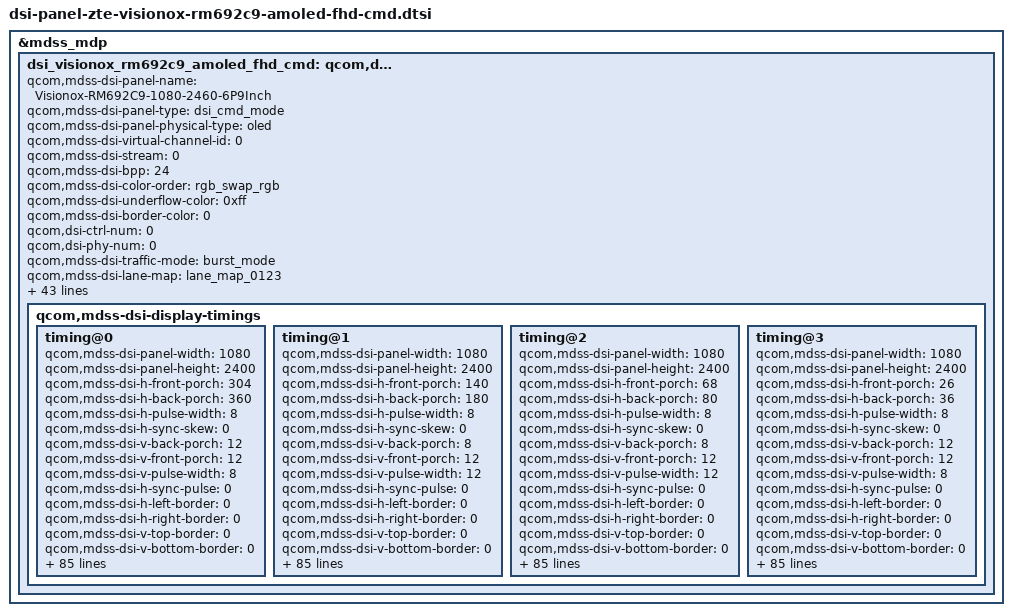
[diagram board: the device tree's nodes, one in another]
&mdss_mdp {
	dsi_visionox_rm692c9_amoled_fhd_cmd: qcom,dsi_visionox_rm692c9_cmd_display {
		qcom,mdss-dsi-panel-name = "Visionox-RM692C9-1080-2460-6P9Inch";
		qcom,mdss-dsi-panel-type = "dsi_cmd_mode";
		qcom,mdss-dsi-panel-physical-type = "oled";
		qcom,mdss-dsi-virtual-channel-id = <0>;
		qcom,mdss-dsi-stream = <0>;
		qcom,mdss-dsi-bpp = <24>;
		qcom,mdss-dsi-color-order = "rgb_swap_rgb";
		qcom,mdss-dsi-underflow-color = <0xff>;
		qcom,mdss-dsi-border-color = <0>;
		qcom,dsi-ctrl-num = <0>;
		qcom,dsi-phy-num = <0>;
		qcom,mdss-dsi-traffic-mode = "burst_mode";
		qcom,mdss-dsi-lane-map = "lane_map_0123";
		qcom,mdss-dsi-bllp-eof-power-mode;
		qcom,mdss-dsi-bllp-power-mode;
		qcom,mdss-dsi-lane-0-state;
		qcom,mdss-dsi-lane-1-state;
		qcom,mdss-dsi-lane-2-state;
		qcom,mdss-dsi-lane-3-state;
		qcom,mdss-dsi-lp11-init;
		qcom,mdss-dsi-tx-eot-append;
		qcom,mdss-dsi-dma-trigger = "trigger_sw";
		qcom,mdss-dsi-mdp-trigger = "none";
		qcom,mdss-dsi-reset-sequence = <1 10 0 10 1 50>;
		qcom,mdss-dsi-te-pin-select = <1>;
		qcom,mdss-dsi-te-dcs-command = <1>;
		qcom,mdss-dsi-te-check-enable;
		qcom,mdss-dsi-te-using-te-pin;
		qcom,mdss-dsi-bl-min-level = <1>;
		qcom,mdss-dsi-bl-max-level = <2047>;
		qcom,mdss-dsi-bl-pmic-control-type = "bl_ctrl_dcs";
		qcom,mdss-dsi-panel-hdr-enabled;
		qcom,mdss-dsi-panel-hdr-color-primaries = <14500 15500 34015 15980 13030 34670 6950 2565>;
		qcom,mdss-dsi-panel-peak-brightness = <6680000>;
		qcom,mdss-dsi-panel-blackness-level = <20>;
		qcom,mdss-pan-physical-width-dimension = <69>;
		qcom,mdss-pan-physical-height-dimension = <155>;
		qcom,bl-dsc-cmd-state = "dsi_lp_mode";
		zte,lcd_dimreg_value = <40>;
		zte,lcd_close_dimreg_value = <32>;
		zte,lcd_aod_bl_reg51_control;
		zte,lcd_hbm_bl_reg51_control;
		zte,lcd_hbm_max_bl = <4095>;
		qcom,panel-supply-entries = <&dsi_panel_pwr_supply>;
		qcom,mdss-brightness-max-level = <255>;
		qcom,platform-reset-gpio = <&tlmm 24 0>;
		zte,disp_iovdd_en_gpio = <&pm8350_gpios 9 1>;
		qcom,dsi-select-clocks = "mux_byte_clk0", "mux_pixel_clk0";
		qcom,dsi-panel-gpio-address = <0xf100000 0x1000>;
		qcom,dsi-panel-gpio-pins = <12 24 82>;
		qcom,dsi-panel-gpio-names = "reg-gpio", "reset-gpio", "platform-te-gpio";

		qcom,mdss-dsi-display-timings {
			timing@0 {
				qcom,mdss-dsi-panel-width = <1080>;
				qcom,mdss-dsi-panel-height = <2400>;
				qcom,mdss-dsi-h-front-porch = <304>;
				qcom,mdss-dsi-h-back-porch = <360>;
				qcom,mdss-dsi-h-pulse-width = <8>;
				qcom,mdss-dsi-h-sync-skew = <0>;
				qcom,mdss-dsi-v-back-porch = <12>;
				qcom,mdss-dsi-v-front-porch = <12>;
				qcom,mdss-dsi-v-pulse-width = <8>;
				qcom,mdss-dsi-h-sync-pulse = <0>;
				qcom,mdss-dsi-h-left-border = <0>;
				qcom,mdss-dsi-h-right-border = <0>;
				qcom,mdss-dsi-v-top-border = <0>;
				qcom,mdss-dsi-v-bottom-border = <0>;
				qcom,mdss-dsi-panel-framerate = <60>;
				qcom,mdss-dsi-panel-clockrate = <903540000>;
				qcom,mdss-dsi-on-command = [15 01 00 00 00 00 02 fe 00
					15 01 00 00 00 00 02 55 00
					15 01 00 00 00 00 02 fe 34
					15 01 00 00 00 00 02 47 03
					15 01 00 00 00 00 02 48 00
					15 01 00 00 00 00 02 00 00
					15 01 00 00 00 00 02 fe 34
					15 01 00 00 00 00 02 9f 38
					15 01 00 00 00 00 02 a0 04
					15 01 00 00 00 00 02 1e 00
					15 01 00 00 00 00 02 1f 00
					15 01 00 00 00 00 02 20 00
					15 01 00 00 00 00 02 22 00
					15 01 00 00 00 00 02 21 70
					15 01 00 00 00 00 02 23 f8
					15 01 00 00 00 00 02 24 77
					15 01 00 00 00 00 02 25 f8
					15 01 00 00 00 00 02 26 f8
					15 01 00 00 00 00 02 2f 00
					15 01 00 00 00 00 02 30 00
					15 01 00 00 00 00 02 31 00
					15 01 00 00 00 00 02 32 00
					15 01 00 00 00 00 02 33 00
					15 01 00 00 00 00 02 34 00
					15 01 00 00 00 00 02 35 00
					15 01 00 00 00 00 02 36 4c
					15 01 00 00 00 00 02 37 00
					15 01 00 00 00 00 02 38 e9
					15 01 00 00 00 00 02 39 01
					15 01 00 00 00 00 02 3a 53
					15 01 00 00 00 00 02 3b 00
					15 01 00 00 00 00 02 3d 00
					15 01 00 00 00 00 02 3f 00
					15 01 00 00 00 00 02 40 00
					15 01 00 00 00 00 02 41 00
					15 01 00 00 00 00 02 42 00
					15 01 00 00 00 00 02 fe 12
					15 01 00 00 05 00 02 83 10
					15 01 00 00 00 00 02 fe 40
					15 01 00 00 00 00 02 bd 00
					15 01 00 00 00 00 02 fe a1
					15 01 00 00 00 00 02 cd 6b
					15 01 00 00 00 00 02 ce bb
					15 01 00 00 00 00 02 fe d1
					15 01 00 00 00 00 02 b4 01
					15 01 00 00 00 00 02 fe 38
					15 01 00 00 00 00 02 17 0f
					15 01 00 00 00 00 02 18 0f
					15 01 00 00 00 00 02 fe 42
					15 01 00 00 00 00 02 21 44
					15 01 00 00 00 00 02 fe 00
					15 01 00 00 00 00 02 fa 01
					15 01 00 00 00 00 02 c2 08
					15 01 00 00 00 00 02 35 00
					39 01 00 00 00 00 03 51 00 00
					05 01 00 00 50 00 01 11
					05 01 00 00 0a 00 01 29
				];
				qcom,mdss-dsi-off-command = [05 01 00 00 64 00 01 28
					05 01 00 00 0a 00 01 10
				];
				qcom,mdss-dsi-on-command-state = "dsi_lp_mode";
				qcom,mdss-dsi-off-command-state = "dsi_lp_mode";
				qcom,mdss-dsi-lp1-command = [15 01 00 00 00 00 02 fe a0
					15 01 00 00 00 00 02 25 c0
					15 01 00 00 00 00 02 fe 00
					05 01 00 00 00 00 01 39
				];
				qcom,mdss-dsi-lp1-command-state = "dsi_lp_mode";
				qcom,mdss-dsi-nolp-command = [15 01 00 00 00 00 02 fe 00
					05 01 00 00 00 00 01 38
					15 01 00 00 00 00 02 fe a0
					15 01 00 00 00 00 02 25 40
					15 01 00 00 00 00 02 fe 00
				];
				qcom,mdss-dsi-nolp-command-state = "dsi_lp_mode";
				qcom,mdss-dsi-timing-switch-command = [15 01 00 00 00 00 02 fe 40
					15 01 00 00 00 00 02 bd 00
					15 01 00 00 00 00 02 fe 00
				];
				qcom,mdss-dsi-timing-switch-command-state = "dsi_lp_mode";
				zte,mdss-dsi-aod-low-commands = [39 01 00 00 00 00 03 51 00 ff];
				zte,mdss-dsi-aod-mid-commands = [39 01 00 00 00 00 03 51 07 ff];
				zte,mdss-dsi-aod-high-commands = [39 01 00 00 00 00 03 51 0f ff];
				zte,mdss-dsi-hbm-on-commands = [15 01 00 00 00 00 02 53 20
					39 01 00 00 00 00 03 51 0f ff
				];
				zte,mdss-dsi-hbm-off-commands = [39 01 00 00 00 00 03 51 03 ff];
				zte,mdss-dsi-global-hbm-on-commands = [15 01 00 00 00 00 02 83 01];
				zte,mdss-dsi-global-hbm-off-commands = [15 01 00 00 00 00 02 83 00];
				zte,mdss-dsi-acl-off-commands = [15 01 00 00 00 00 02 fe 00
					15 01 00 00 00 00 02 55 00
				];
				zte,mdss-dsi-acl-low-commands = [15 01 00 00 00 00 02 fe 00
					15 01 00 00 00 00 02 55 01
				];
				zte,mdss-dsi-acl-mid-commands = [15 01 00 00 00 00 02 fe 00
					15 01 00 00 00 00 02 55 02
				];
				zte,mdss-dsi-acl-high-commands = [15 01 00 00 00 00 02 fe 00
					15 01 00 00 00 00 02 55 03
				];
				zte,mdss-dsi-elvdd-46-commands = [15 01 00 00 00 00 02 fe 40
					15 01 00 00 00 00 02 b2 54
					15 01 00 00 00 00 02 fe 00
				];
				zte,mdss-dsi-color-original-commands = [15 01 00 00 00 00 02 fe 12
					15 01 00 00 00 00 02 83 00
					15 01 00 00 05 00 02 fe 00
				];
				zte,mdss-dsi-color-srgb-commands = [15 01 00 00 00 00 02 fe 12
					15 01 00 00 00 00 02 83 20
					15 01 00 00 05 00 02 fe 00
				];
				zte,mdss-dsi-color-p3-commands = [15 01 00 00 00 00 02 fe 12
					15 01 00 00 00 00 02 83 10
					15 01 00 00 05 00 02 fe 00
				];
				zte,mdss-dsi-color-original-commands-state = "dsi_lp_mode";
				zte,mdss-dsi-color-srgb-commands-state = "dsi_lp_mode";
				zte,mdss-dsi-color-p3-commands-state = "dsi_lp_mode";
				zte,mdss-dsi-hbm-on-commands-state = "dsi_lp_mode";
				zte,mdss-dsi-hbm-off-commands-state = "dsi_lp_mode";
				zte,mdss-dsi-aod-low-commands-state = "dsi_lp_mode";
				zte,mdss-dsi-aod-mid-commands-state = "dsi_lp_mode";
				zte,mdss-dsi-aod-high-commands-state = "dsi_lp_mode";
				zte,mdss-dsi-acl-off-commands-state = "dsi_lp_mode";
				zte,mdss-dsi-acl-low-commands-state = "dsi_lp_mode";
				zte,mdss-dsi-acl-mid-commands-state = "dsi_lp_mode";
				zte,mdss-dsi-acl-high-commands-state = "dsi_lp_mode";
				zte,mdss-dsi-elvdd-46-commands-state = "dsi_lp_mode";
				qcom,compression-mode = "dsc";
				qcom,mdss-dsc-slice-height = <20>;
				qcom,mdss-dsc-slice-width = <540>;
				qcom,mdss-dsc-slice-per-pkt = <2>;
				qcom,mdss-dsc-bit-per-component = <8>;
				qcom,mdss-dsc-bit-per-pixel = <8>;
				qcom,mdss-dsc-block-prediction-enable;
				qcom,mdss-dsi-panel-phy-timings = [00 1e 08 07 18 16 08 08 08 02 04 00 1a 0d];
				qcom,display-topology = <2 2 1>;
				qcom,default-topology-index = <0>;
			};

			timing@1 {
				qcom,mdss-dsi-panel-width = <1080>;
				qcom,mdss-dsi-panel-height = <2400>;
				qcom,mdss-dsi-h-front-porch = <140>;
				qcom,mdss-dsi-h-back-porch = <180>;
				qcom,mdss-dsi-h-pulse-width = <8>;
				qcom,mdss-dsi-h-sync-skew = <0>;
				qcom,mdss-dsi-v-back-porch = <8>;
				qcom,mdss-dsi-v-front-porch = <12>;
				qcom,mdss-dsi-v-pulse-width = <12>;
				qcom,mdss-dsi-h-sync-pulse = <0>;
				qcom,mdss-dsi-h-left-border = <0>;
				qcom,mdss-dsi-h-right-border = <0>;
				qcom,mdss-dsi-v-top-border = <0>;
				qcom,mdss-dsi-v-bottom-border = <0>;
				qcom,mdss-dsi-panel-framerate = <90>;
				qcom,mdss-dsi-panel-clockrate = <903640000>;
				qcom,mdss-dsi-on-command = [15 01 00 00 00 00 02 fe 00
					15 01 00 00 00 00 02 55 00
					15 01 00 00 00 00 02 fe 34
					15 01 00 00 00 00 02 47 03
					15 01 00 00 00 00 02 48 00
					15 01 00 00 00 00 02 00 00
					15 01 00 00 00 00 02 fe 34
					15 01 00 00 00 00 02 9f 38
					15 01 00 00 00 00 02 a0 04
					15 01 00 00 00 00 02 1e 00
					15 01 00 00 00 00 02 1f 00
					15 01 00 00 00 00 02 20 00
					15 01 00 00 00 00 02 22 00
					15 01 00 00 00 00 02 21 70
					15 01 00 00 00 00 02 23 f8
					15 01 00 00 00 00 02 24 77
					15 01 00 00 00 00 02 25 f8
					15 01 00 00 00 00 02 26 f8
					15 01 00 00 00 00 02 2f 00
					15 01 00 00 00 00 02 30 00
					15 01 00 00 00 00 02 31 00
					15 01 00 00 00 00 02 32 00
					15 01 00 00 00 00 02 33 00
					15 01 00 00 00 00 02 34 00
					15 01 00 00 00 00 02 35 00
					15 01 00 00 00 00 02 36 4c
					15 01 00 00 00 00 02 37 00
					15 01 00 00 00 00 02 38 e9
					15 01 00 00 00 00 02 39 01
					15 01 00 00 00 00 02 3a 53
					15 01 00 00 00 00 02 3b 00
					15 01 00 00 00 00 02 3d 00
					15 01 00 00 00 00 02 3f 00
					15 01 00 00 00 00 02 40 00
					15 01 00 00 00 00 02 41 00
					15 01 00 00 00 00 02 42 00
					15 01 00 00 00 00 02 fe 12
					15 01 00 00 05 00 02 83 10
					15 01 00 00 00 00 02 fe 40
					15 01 00 00 00 00 02 bd 05
					15 01 00 00 00 00 02 fe a1
					15 01 00 00 00 00 02 cd 6b
					15 01 00 00 00 00 02 ce bb
					15 01 00 00 00 00 02 fe d1
					15 01 00 00 00 00 02 b4 01
					15 01 00 00 00 00 02 fe 38
					15 01 00 00 00 00 02 17 0f
					15 01 00 00 00 00 02 18 0f
					15 01 00 00 00 00 02 fe 42
					15 01 00 00 00 00 02 21 44
					15 01 00 00 00 00 02 fe 00
					15 01 00 00 00 00 02 fa 01
					15 01 00 00 00 00 02 c2 08
					15 01 00 00 00 00 02 35 00
					39 01 00 00 00 00 03 51 00 00
					05 01 00 00 50 00 01 11
					05 01 00 00 0a 00 01 29
				];
				qcom,mdss-dsi-off-command = [05 01 00 00 64 00 01 28
					05 01 00 00 0a 00 01 10
				];
				qcom,mdss-dsi-on-command-state = "dsi_lp_mode";
				qcom,mdss-dsi-off-command-state = "dsi_lp_mode";
				qcom,mdss-dsi-lp1-command = [15 01 00 00 00 00 02 fe a0
					15 01 00 00 00 00 02 25 c0
					15 01 00 00 00 00 02 fe 00
					05 01 00 00 00 00 01 39
				];
				qcom,mdss-dsi-lp1-command-state = "dsi_lp_mode";
				qcom,mdss-dsi-nolp-command = [15 01 00 00 00 00 02 fe 00
					05 01 00 00 00 00 01 38
					15 01 00 00 00 00 02 fe a0
					15 01 00 00 00 00 02 25 40
					15 01 00 00 00 00 02 fe 00
				];
				qcom,mdss-dsi-nolp-command-state = "dsi_lp_mode";
				qcom,mdss-dsi-timing-switch-command = [15 01 00 00 00 00 02 fe 40
					15 01 00 00 00 00 02 bd 05
					15 01 00 00 00 00 02 fe 00
				];
				qcom,mdss-dsi-timing-switch-command-state = "dsi_lp_mode";
				zte,mdss-dsi-aod-low-commands = [39 01 00 00 00 00 03 51 00 ff];
				zte,mdss-dsi-aod-mid-commands = [39 01 00 00 00 00 03 51 07 ff];
				zte,mdss-dsi-aod-high-commands = [39 01 00 00 00 00 03 51 0f ff];
				zte,mdss-dsi-hbm-on-commands = [15 01 00 00 00 00 02 53 20
					39 01 00 00 00 00 03 51 0f ff
				];
				zte,mdss-dsi-hbm-off-commands = [39 01 00 00 00 00 03 51 03 ff];
				zte,mdss-dsi-global-hbm-on-commands = [15 01 00 00 00 00 02 83 01];
				zte,mdss-dsi-global-hbm-off-commands = [15 01 00 00 00 00 02 83 00];
				zte,mdss-dsi-acl-off-commands = [15 01 00 00 00 00 02 fe 00
					15 01 00 00 00 00 02 55 00
				];
				zte,mdss-dsi-acl-low-commands = [15 01 00 00 00 00 02 fe 00
					15 01 00 00 00 00 02 55 01
				];
				zte,mdss-dsi-acl-mid-commands = [15 01 00 00 00 00 02 fe 00
					15 01 00 00 00 00 02 55 02
				];
				zte,mdss-dsi-acl-high-commands = [15 01 00 00 00 00 02 fe 00
					15 01 00 00 00 00 02 55 03
				];
				zte,mdss-dsi-elvdd-46-commands = [15 01 00 00 00 00 02 fe 40
					15 01 00 00 00 00 02 b2 54
					15 01 00 00 00 00 02 fe 00
				];
				zte,mdss-dsi-color-original-commands = [15 01 00 00 00 00 02 fe 12
					15 01 00 00 00 00 02 83 00
					15 01 00 00 05 00 02 fe 00
				];
				zte,mdss-dsi-color-srgb-commands = [15 01 00 00 00 00 02 fe 12
					15 01 00 00 00 00 02 83 20
					15 01 00 00 05 00 02 fe 00
				];
				zte,mdss-dsi-color-p3-commands = [15 01 00 00 00 00 02 fe 12
					15 01 00 00 00 00 02 83 10
					15 01 00 00 05 00 02 fe 00
				];
				zte,mdss-dsi-color-original-commands-state = "dsi_lp_mode";
				zte,mdss-dsi-color-srgb-commands-state = "dsi_lp_mode";
				zte,mdss-dsi-color-p3-commands-state = "dsi_lp_mode";
				zte,mdss-dsi-hbm-on-commands-state = "dsi_lp_mode";
				zte,mdss-dsi-hbm-off-commands-state = "dsi_lp_mode";
				zte,mdss-dsi-aod-low-commands-state = "dsi_lp_mode";
				zte,mdss-dsi-aod-mid-commands-state = "dsi_lp_mode";
				zte,mdss-dsi-aod-high-commands-state = "dsi_lp_mode";
				zte,mdss-dsi-acl-off-commands-state = "dsi_lp_mode";
				zte,mdss-dsi-acl-low-commands-state = "dsi_lp_mode";
				zte,mdss-dsi-acl-mid-commands-state = "dsi_lp_mode";
				zte,mdss-dsi-acl-high-commands-state = "dsi_lp_mode";
				zte,mdss-dsi-elvdd-46-commands-state = "dsi_lp_mode";
				qcom,compression-mode = "dsc";
				qcom,mdss-dsc-slice-height = <20>;
				qcom,mdss-dsc-slice-width = <540>;
				qcom,mdss-dsc-slice-per-pkt = <2>;
				qcom,mdss-dsc-bit-per-component = <8>;
				qcom,mdss-dsc-bit-per-pixel = <8>;
				qcom,mdss-dsc-block-prediction-enable;
				qcom,mdss-dsi-panel-phy-timings = [00 1e 08 07 18 16 08 08 08 02 04 00 1a 0d];
				qcom,display-topology = <2 2 1>;
				qcom,default-topology-index = <0>;
			};

			timing@2 {
				qcom,mdss-dsi-panel-width = <1080>;
				qcom,mdss-dsi-panel-height = <2400>;
				qcom,mdss-dsi-h-front-porch = <68>;
				qcom,mdss-dsi-h-back-porch = <80>;
				qcom,mdss-dsi-h-pulse-width = <8>;
				qcom,mdss-dsi-h-sync-skew = <0>;
				qcom,mdss-dsi-v-back-porch = <8>;
				qcom,mdss-dsi-v-front-porch = <12>;
				qcom,mdss-dsi-v-pulse-width = <12>;
				qcom,mdss-dsi-h-sync-pulse = <0>;
				qcom,mdss-dsi-h-left-border = <0>;
				qcom,mdss-dsi-h-right-border = <0>;
				qcom,mdss-dsi-v-top-border = <0>;
				qcom,mdss-dsi-v-bottom-border = <0>;
				qcom,mdss-dsi-panel-framerate = <120>;
				qcom,mdss-dsi-panel-clockrate = <903740000>;
				qcom,mdss-dsi-on-command = [15 01 00 00 00 00 02 fe 00
					15 01 00 00 00 00 02 55 00
					15 01 00 00 00 00 02 fe 34
					15 01 00 00 00 00 02 47 03
					15 01 00 00 00 00 02 48 00
					15 01 00 00 00 00 02 00 00
					15 01 00 00 00 00 02 fe 34
					15 01 00 00 00 00 02 47 03
					15 01 00 00 00 00 02 48 00
					15 01 00 00 00 00 02 00 00
					15 01 00 00 00 00 02 fe 34
					15 01 00 00 00 00 02 9f 38
					15 01 00 00 00 00 02 a0 04
					15 01 00 00 00 00 02 1e 00
					15 01 00 00 00 00 02 1f 00
					15 01 00 00 00 00 02 20 00
					15 01 00 00 00 00 02 22 00
					15 01 00 00 00 00 02 21 70
					15 01 00 00 00 00 02 23 f8
					15 01 00 00 00 00 02 24 77
					15 01 00 00 00 00 02 25 f8
					15 01 00 00 00 00 02 26 f8
					15 01 00 00 00 00 02 2f 00
					15 01 00 00 00 00 02 30 00
					15 01 00 00 00 00 02 31 00
					15 01 00 00 00 00 02 32 00
					15 01 00 00 00 00 02 33 00
					15 01 00 00 00 00 02 34 00
					15 01 00 00 00 00 02 35 00
					15 01 00 00 00 00 02 36 4c
					15 01 00 00 00 00 02 37 00
					15 01 00 00 00 00 02 38 e9
					15 01 00 00 00 00 02 39 01
					15 01 00 00 00 00 02 3a 53
					15 01 00 00 00 00 02 3b 00
					15 01 00 00 00 00 02 3d 00
					15 01 00 00 00 00 02 3f 00
					15 01 00 00 00 00 02 40 00
					15 01 00 00 00 00 02 41 00
					15 01 00 00 00 00 02 42 00
					15 01 00 00 00 00 02 fe 12
					15 01 00 00 05 00 02 83 10
					15 01 00 00 00 00 02 fe 40
					15 01 00 00 00 00 02 bd 06
					15 01 00 00 00 00 02 fe a1
					15 01 00 00 00 00 02 cd 6b
					15 01 00 00 00 00 02 ce bb
					15 01 00 00 00 00 02 fe d1
					15 01 00 00 00 00 02 b4 01
					15 01 00 00 00 00 02 fe 38
					15 01 00 00 00 00 02 17 0f
					15 01 00 00 00 00 02 18 0f
					15 01 00 00 00 00 02 fe 42
					15 01 00 00 00 00 02 21 44
					15 01 00 00 00 00 02 fe 00
					15 01 00 00 00 00 02 fa 01
					15 01 00 00 00 00 02 c2 08
					15 01 00 00 00 00 02 35 00
					39 01 00 00 00 00 03 51 00 00
					05 01 00 00 50 00 01 11
					05 01 00 00 0a 00 01 29
				];
				qcom,mdss-dsi-off-command = [05 01 00 00 64 00 01 28
					05 01 00 00 0a 00 01 10
				];
				qcom,mdss-dsi-lp1-command = [15 01 00 00 00 00 02 fe a0
					15 01 00 00 00 00 02 25 c0
					15 01 00 00 00 00 02 fe 00
					05 01 00 00 00 00 01 39
				];
				qcom,mdss-dsi-lp1-command-state = "dsi_lp_mode";
				qcom,mdss-dsi-nolp-command = [15 01 00 00 00 00 02 fe 00
					05 01 00 00 00 00 01 38
					15 01 00 00 00 00 02 fe a0
					15 01 00 00 00 00 02 25 40
					15 01 00 00 00 00 02 fe 00
				];
				qcom,mdss-dsi-nolp-command-state = "dsi_lp_mode";
				qcom,mdss-dsi-on-command-state = "dsi_lp_mode";
				qcom,mdss-dsi-off-command-state = "dsi_lp_mode";
				qcom,mdss-dsi-timing-switch-command = [15 01 00 00 00 00 02 fe 40
					15 01 00 00 00 00 02 bd 06
					15 01 00 00 00 00 02 fe 00
				];
				qcom,mdss-dsi-timing-switch-command-state = "dsi_lp_mode";
				zte,mdss-dsi-aod-low-commands = [39 01 00 00 00 00 03 51 00 ff];
				zte,mdss-dsi-aod-mid-commands = [39 01 00 00 00 00 03 51 07 ff];
				zte,mdss-dsi-aod-high-commands = [39 01 00 00 00 00 03 51 0f ff];
				zte,mdss-dsi-hbm-on-commands = [15 01 00 00 00 00 02 53 20
					39 01 00 00 00 00 03 51 0f ff
				];
				zte,mdss-dsi-hbm-off-commands = [39 01 00 00 00 00 03 51 03 ff];
				zte,mdss-dsi-global-hbm-on-commands = [15 01 00 00 00 00 02 83 01];
				zte,mdss-dsi-global-hbm-off-commands = [15 01 00 00 00 00 02 83 00];
				zte,mdss-dsi-acl-off-commands = [15 01 00 00 00 00 02 fe 00
					15 01 00 00 00 00 02 55 00
				];
				zte,mdss-dsi-acl-low-commands = [15 01 00 00 00 00 02 fe 00
					15 01 00 00 00 00 02 55 01
				];
				zte,mdss-dsi-acl-mid-commands = [15 01 00 00 00 00 02 fe 00
					15 01 00 00 00 00 02 55 02
				];
				zte,mdss-dsi-acl-high-commands = [15 01 00 00 00 00 02 fe 00
					15 01 00 00 00 00 02 55 03
				];
				zte,mdss-dsi-elvdd-46-commands = [15 01 00 00 00 00 02 fe 40
					15 01 00 00 00 00 02 b2 54
					15 01 00 00 00 00 02 fe 00
				];
				zte,mdss-dsi-color-original-commands = [15 01 00 00 00 00 02 fe 12
					15 01 00 00 00 00 02 83 00
					15 01 00 00 05 00 02 fe 00
				];
				zte,mdss-dsi-color-srgb-commands = [15 01 00 00 00 00 02 fe 12
					15 01 00 00 00 00 02 83 20
					15 01 00 00 05 00 02 fe 00
				];
				zte,mdss-dsi-color-p3-commands = [15 01 00 00 00 00 02 fe 12
					15 01 00 00 00 00 02 83 10
					15 01 00 00 05 00 02 fe 00
				];
				zte,mdss-dsi-color-original-commands-state = "dsi_lp_mode";
				zte,mdss-dsi-color-srgb-commands-state = "dsi_lp_mode";
				zte,mdss-dsi-color-p3-commands-state = "dsi_lp_mode";
				zte,mdss-dsi-hbm-on-commands-state = "dsi_lp_mode";
				zte,mdss-dsi-hbm-off-commands-state = "dsi_lp_mode";
				zte,mdss-dsi-aod-low-commands-state = "dsi_lp_mode";
				zte,mdss-dsi-aod-mid-commands-state = "dsi_lp_mode";
				zte,mdss-dsi-aod-high-commands-state = "dsi_lp_mode";
				zte,mdss-dsi-acl-off-commands-state = "dsi_lp_mode";
				zte,mdss-dsi-acl-low-commands-state = "dsi_lp_mode";
				zte,mdss-dsi-acl-mid-commands-state = "dsi_lp_mode";
				zte,mdss-dsi-acl-high-commands-state = "dsi_lp_mode";
				zte,mdss-dsi-elvdd-46-commands-state = "dsi_lp_mode";
				qcom,compression-mode = "dsc";
				qcom,mdss-dsc-slice-height = <20>;
				qcom,mdss-dsc-slice-width = <540>;
				qcom,mdss-dsc-slice-per-pkt = <2>;
				qcom,mdss-dsc-bit-per-component = <8>;
				qcom,mdss-dsc-bit-per-pixel = <8>;
				qcom,mdss-dsc-block-prediction-enable;
				qcom,mdss-dsi-panel-phy-timings = [00 1e 08 07 18 16 08 08 08 02 04 00 1a 0d];
				qcom,display-topology = <2 2 1>;
				qcom,default-topology-index = <0>;
			};

			timing@3 {
				qcom,mdss-dsi-panel-width = <1080>;
				qcom,mdss-dsi-panel-height = <2400>;
				qcom,mdss-dsi-h-front-porch = <26>;
				qcom,mdss-dsi-h-back-porch = <36>;
				qcom,mdss-dsi-h-pulse-width = <8>;
				qcom,mdss-dsi-h-sync-skew = <0>;
				qcom,mdss-dsi-v-back-porch = <12>;
				qcom,mdss-dsi-v-front-porch = <12>;
				qcom,mdss-dsi-v-pulse-width = <8>;
				qcom,mdss-dsi-h-sync-pulse = <0>;
				qcom,mdss-dsi-h-left-border = <0>;
				qcom,mdss-dsi-h-right-border = <0>;
				qcom,mdss-dsi-v-top-border = <0>;
				qcom,mdss-dsi-v-bottom-border = <0>;
				qcom,mdss-dsi-panel-framerate = <144>;
				qcom,mdss-dsi-panel-clockrate = <903840000>;
				qcom,mdss-dsi-on-command = [15 01 00 00 00 00 02 fe 00
					15 01 00 00 00 00 02 55 00
					15 01 00 00 00 00 02 fe 34
					15 01 00 00 00 00 02 47 03
					15 01 00 00 00 00 02 48 00
					15 01 00 00 00 00 02 00 00
					15 01 00 00 00 00 02 fe 34
					15 01 00 00 00 00 02 9f 38
					15 01 00 00 00 00 02 a0 04
					15 01 00 00 00 00 02 1e 00
					15 01 00 00 00 00 02 1f 00
					15 01 00 00 00 00 02 20 00
					15 01 00 00 00 00 02 22 00
					15 01 00 00 00 00 02 21 70
					15 01 00 00 00 00 02 23 f8
					15 01 00 00 00 00 02 24 77
					15 01 00 00 00 00 02 25 f8
					15 01 00 00 00 00 02 26 f8
					15 01 00 00 00 00 02 2f 00
					15 01 00 00 00 00 02 30 00
					15 01 00 00 00 00 02 31 00
					15 01 00 00 00 00 02 32 00
					15 01 00 00 00 00 02 33 00
					15 01 00 00 00 00 02 34 00
					15 01 00 00 00 00 02 35 00
					15 01 00 00 00 00 02 36 4c
					15 01 00 00 00 00 02 37 00
					15 01 00 00 00 00 02 38 e9
					15 01 00 00 00 00 02 39 01
					15 01 00 00 00 00 02 3a 53
					15 01 00 00 00 00 02 3b 00
					15 01 00 00 00 00 02 3d 00
					15 01 00 00 00 00 02 3f 00
					15 01 00 00 00 00 02 40 00
					15 01 00 00 00 00 02 41 00
					15 01 00 00 00 00 02 42 00
					15 01 00 00 00 00 02 fe 12
					15 01 00 00 05 00 02 83 10
					15 01 00 00 00 00 02 fe 40
					15 01 00 00 00 00 02 bd 07
					15 01 00 00 00 00 02 fe a1
					15 01 00 00 00 00 02 cd 6b
					15 01 00 00 00 00 02 ce bb
					15 01 00 00 00 00 02 fe d1
					15 01 00 00 00 00 02 b4 01
					15 01 00 00 00 00 02 fe 38
					15 01 00 00 00 00 02 17 0f
					15 01 00 00 00 00 02 18 0f
					15 01 00 00 00 00 02 fe 42
					15 01 00 00 00 00 02 21 44
					15 01 00 00 00 00 02 fe 00
					15 01 00 00 00 00 02 fa 01
					15 01 00 00 00 00 02 c2 08
					15 01 00 00 00 00 02 35 00
					39 01 00 00 00 00 03 51 00 00
					05 01 00 00 50 00 01 11
					05 01 00 00 0a 00 01 29
				];
				qcom,mdss-dsi-off-command = [05 01 00 00 64 00 01 28
					05 01 00 00 0a 00 01 10
				];
				qcom,mdss-dsi-on-command-state = "dsi_lp_mode";
				qcom,mdss-dsi-off-command-state = "dsi_lp_mode";
				qcom,mdss-dsi-lp1-command = [15 01 00 00 00 00 02 fe a0
					15 01 00 00 00 00 02 25 c0
					15 01 00 00 00 00 02 fe 00
					05 01 00 00 00 00 01 39
				];
				qcom,mdss-dsi-lp1-command-state = "dsi_lp_mode";
				qcom,mdss-dsi-nolp-command = [15 01 00 00 00 00 02 fe 00
					05 01 00 00 00 00 01 38
					15 01 00 00 00 00 02 fe a0
					15 01 00 00 00 00 02 25 40
					15 01 00 00 00 00 02 fe 00
				];
				qcom,mdss-dsi-nolp-command-state = "dsi_lp_mode";
				qcom,mdss-dsi-timing-switch-command = [15 01 00 00 00 00 02 fe 40
					15 01 00 00 00 00 02 bd 07
					15 01 00 00 00 00 02 fe 00
				];
				qcom,mdss-dsi-timing-switch-command-state = "dsi_lp_mode";
				zte,mdss-dsi-aod-low-commands = [39 01 00 00 00 00 03 51 00 ff];
				zte,mdss-dsi-aod-mid-commands = [39 01 00 00 00 00 03 51 07 ff];
				zte,mdss-dsi-aod-high-commands = [39 01 00 00 00 00 03 51 0f ff];
				zte,mdss-dsi-hbm-on-commands = [15 01 00 00 00 00 02 53 20
					39 01 00 00 00 00 03 51 0f ff
				];
				zte,mdss-dsi-hbm-off-commands = [39 01 00 00 00 00 03 51 03 ff];
				zte,mdss-dsi-global-hbm-on-commands = [15 01 00 00 00 00 02 83 01];
				zte,mdss-dsi-global-hbm-off-commands = [15 01 00 00 00 00 02 83 00];
				zte,mdss-dsi-acl-off-commands = [15 01 00 00 00 00 02 fe 00
					15 01 00 00 00 00 02 55 00
				];
				zte,mdss-dsi-acl-low-commands = [15 01 00 00 00 00 02 fe 00
					15 01 00 00 00 00 02 55 01
				];
				zte,mdss-dsi-acl-mid-commands = [15 01 00 00 00 00 02 fe 00
					15 01 00 00 00 00 02 55 02
				];
				zte,mdss-dsi-acl-high-commands = [15 01 00 00 00 00 02 fe 00
					15 01 00 00 00 00 02 55 03
				];
				zte,mdss-dsi-elvdd-46-commands = [15 01 00 00 00 00 02 fe 40
					15 01 00 00 00 00 02 b2 54
					15 01 00 00 00 00 02 fe 00
				];
				zte,mdss-dsi-color-original-commands = [15 01 00 00 00 00 02 fe 12
					15 01 00 00 00 00 02 83 00
					15 01 00 00 05 00 02 fe 00
				];
				zte,mdss-dsi-color-srgb-commands = [15 01 00 00 00 00 02 fe 12
					15 01 00 00 00 00 02 83 20
					15 01 00 00 05 00 02 fe 00
				];
				zte,mdss-dsi-color-p3-commands = [15 01 00 00 00 00 02 fe 12
					15 01 00 00 00 00 02 83 10
					15 01 00 00 05 00 02 fe 00
				];
				zte,mdss-dsi-color-original-commands-state = "dsi_lp_mode";
				zte,mdss-dsi-color-srgb-commands-state = "dsi_lp_mode";
				zte,mdss-dsi-color-p3-commands-state = "dsi_lp_mode";
				zte,mdss-dsi-hbm-on-commands-state = "dsi_lp_mode";
				zte,mdss-dsi-hbm-off-commands-state = "dsi_lp_mode";
				zte,mdss-dsi-aod-low-commands-state = "dsi_lp_mode";
				zte,mdss-dsi-aod-mid-commands-state = "dsi_lp_mode";
				zte,mdss-dsi-aod-high-commands-state = "dsi_lp_mode";
				zte,mdss-dsi-acl-off-commands-state = "dsi_lp_mode";
				zte,mdss-dsi-acl-low-commands-state = "dsi_lp_mode";
				zte,mdss-dsi-acl-mid-commands-state = "dsi_lp_mode";
				zte,mdss-dsi-acl-high-commands-state = "dsi_lp_mode";
				zte,mdss-dsi-elvdd-46-commands-state = "dsi_lp_mode";
				qcom,compression-mode = "dsc";
				qcom,mdss-dsc-slice-height = <20>;
				qcom,mdss-dsc-slice-width = <540>;
				qcom,mdss-dsc-slice-per-pkt = <2>;
				qcom,mdss-dsc-bit-per-component = <8>;
				qcom,mdss-dsc-bit-per-pixel = <8>;
				qcom,mdss-dsc-block-prediction-enable;
				qcom,mdss-dsi-panel-phy-timings = [00 1e 08 07 18 16 08 08 08 02 04 00 1a 0d];
				qcom,display-topology = <2 2 1>;
				qcom,default-topology-index = <0>;
			};
		};
	};
};
